# USB_USB2SS_OPER_31000020h register map
Vendor: Texas Instruments
Peripheral module from a debugger description file (folder am62D).
Registers are 32-bit, read-write, reset 0x0 unless marked. A register's access mark holds for its fields unless they carry their own. Offsets are as the file gives them; lines under a group give offsets from that group; [hi:lo] are bit positions; {n}, {i} and the like mark numbered series; 'fields as' and 'values as' point back to an identical list; <NAME> marks a mode.

## USB2SS_OPER
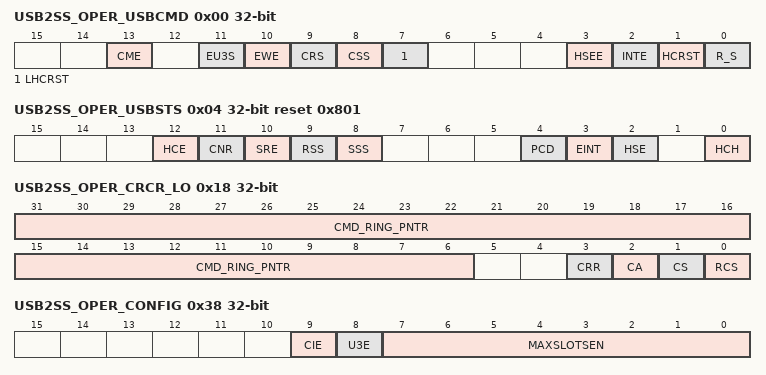
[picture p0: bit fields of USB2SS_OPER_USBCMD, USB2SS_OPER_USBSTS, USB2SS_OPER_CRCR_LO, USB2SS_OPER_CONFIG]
0x00 USB2SS_OPER_USBCMD — USB Command RegisterFor a description of this standard USB register field see the eXtensible Host Controller Interface for Universal Serial Bus (USB) Specification 3.0.
  [13] CME — CEM EnableFor a description of this standard USB register field, see the eXtensible Host Controller Interface for Universal Serial Bus [USB] Specification 3.0. Reset Source: rst_mod_g_rst_n
  [11] EU3S — EU3SFor a description of this standard USB register field, see the eXtensible Host Controller Interface for Universal Serial Bus [USB] Specification 3.0. Reset Source: rst_mod_g_rst_n
  [10] EWE — EWEFor a description of this standard USB register field, see the eXtensible Host Controller Interface for Universal Serial Bus [USB] Specification 3.0. Reset Source: rst_mod_g_rst_n
  [9] CRS — Controller Restore StateThis command is similar to the USBCMD.CRS bit in host mode and initiates the restore process. When software sets this bit to '1', the controller immediately sets DSTS.RSS to '1'. When the controller has finished the restore process, it sets DSTS.RSS to '0'.Note: When read, this field always returns '0'. Reset Source: rst_mod_g_rst_n
  [8] CSS — Controller Save StateThis command is similar to the USBCMD.CSS bit in host mode and initiates the save process. When software sets this bit to '1', the controller immediately sets DSTS.SSS to '1'. When the controller has finished the save process, it sets DSTS.SSS to '0'.Note: When read, this field always returns '0'. Reset Source: rst_mod_g_rst_n
  [7] LHCRST — Light Host Controller ResetFor a description of this standard USB register field, see the eXtensible Host Controller Interface for Universal Serial Bus [USB] Specification 3.0.The following bits reset the internal logic of the host controller. Under soft reset, some CSR accesses may fail [Timeout]. - HCRST - LHCRSTBit Bash register testing is not recommended. Reset Source: rst_mod_g_rst_n
  [3] HSEE — HSEEFor a description of this standard USB register field, see the eXtensible Host Controller Interface for Universal Serial Bus [USB] Specification 3.0. Reset Source: rst_mod_g_rst_n
  [2] INTE — INTEFor a description of this standard USB register field, see the eXtensible Host Controller Interface for Universal Serial Bus [USB] Specification 3.0. Reset Source: rst_mod_g_rst_n
  [1] HCRST — HCRSTThe following bits reset the internal logic of the host controller. Under soft reset, some CSR accesses may fail [Timeout]. - HCRST - LHCRSTBit Bash register testing is not recommended. Reset Source: rst_mod_g_rst_n
  [0] R_S — R_SFor a description of this standard USB register field, see the eXtensible Host Controller Interface for Universal Serial Bus [USB] Specification 3.0.Due to side-effects this reguster field is not recommended for Bit-Bash testing. Reset Source: rst_mod_g_rst_n
0x04 USB2SS_OPER_USBSTS access not given reset 0x801 — USB Status Register Bit DefinitionsFor a description of this standard USB register field, see the eXtensible Host Controller Interface for Universal Serial Bus (USB) Specification 3.0.
  [12] HCE ro — Host Controller Error [HCE] - RO Default = 0. '0' = No internal xHC error conditions exist and '1' = Internal xHC error condition. This flag must be set to indicate that an internal error condition has been detected which requires software to reset and reinitialize the xHC. Refer to section 4.24.1 of the Databook for more information. Reset Source: rst_mod_g_rst_n
  [11] CNR ro — Controller Not Ready [CNR] - RO Default = '1'. '0' = Ready and '1' = Not Ready. Software must not write to thes Doorbell or Operational register of the xHC, other than the USBSTS register, until CNR = '0'. This flag is set by the xHC after a Chip Hardware Reset and cleared when the xHC is ready to begin accepting register writes. This flag remains cleared ['0'] until the next Chip Hardware Reset. Reset Source: rst_mod_g_rst_n
  [10] SRE — Save/Restore ErrorThis bit is currently not supported. Reset Source: rst_mod_g_rst_n (access R/W1TC)
  [9] RSS ro — Restore State Status This bit is similar to the USBSTS.RSS in host mode.When the controller has finished the restore process, it completes the command by setting DSTS.RSS to '0'. Reset Source: rst_mod_g_rst_n
  [8] SSS ro — Save State StatusThis bit is similar to the USBSTS.SSS in host mode.When the controller has finished the save process, it completes the command by setting DSTS.SSS to '0'. Reset Source: rst_mod_g_rst_n
  [4] PCD — Reset Value for PCD Reset Source: rst_mod_g_rst_n (access R/W1TC)
  [3] EINT — Reset Value for EINT Reset Source: rst_mod_g_rst_n (access R/W1TC)
  [2] HSE — HSEFor a description of this standard USB register field, see the eXtensible Host Controller Interface for Universal Serial Bus [USB] Specification 3.0.. Reset Source: rst_mod_g_rst_n (access R/W1TC)
  [0] HCH ro — HCHFor a description of this standard USB register field, see the eXtensible Host Controller Interface for Universal Serial Bus [USB] Specification 3.0. Reset Source: rst_mod_g_rst_n
0x08 USB2SS_OPER_PAGESIZE ro reset 0x1 — Page Size Register Bit DefinitionsUse this register to enable or disable the reporting of specific USB Device Notification Transaction Packets being received.A Notification Enable (Nx, where x = 0 to 15) flag is defined for each of the 16 possible device notification types. If a flag is set for a specific notification type, a Device Notification Event is generated when the respective notification packet is received. After reset, all notifications are disabled. Refer to section 6.4.2.7 of the Databook for more information.This register is written as a Dword. Byte writes produce undefined results.
  [15:0] PAGE_SIZE — PAGE_SIZE Reset Source: rst_mod_g_rst_n
0x14 USB2SS_OPER_DNCTRL — Device Notification Register Bit DefinitionsFor a description of this standard USB register field see the eXtensible Host Controller Interface for Universal Serial Bus (USB) Specification 3.0.
  [15:0] N0_N15 — N0_N15For a description of this standard USB register field see the eXtensible Host Controller Interface for Universal Serial Bus [USB] Specification 3.0. Reset Source: rst_mod_g_rst_n
0x18 USB2SS_OPER_CRCR_LO access per field — CRCR_LOFor a description of this standard USB register field, see the eXtensible Host Controller Interface for Universal Serial Bus (USB) Specification 3.0.
  [31:6] CMD_RING_PNTR wo — CMD_RING_PNTRFor a description of this standard USB register field, see the eXtensible Host Controller Interface for Universal Serial Bus [USB] Specification 3.0. Reset Source: rst_mod_g_rst_n
  [3] CRR ro — CRRFor a description of this standard USB register field, see the eXtensible Host Controller Interface for Universal Serial Bus [USB] Specification 3.0. Reset Source: rst_mod_g_rst_n
  [2] CA wo — CAFor a description of this standard USB register field, see the eXtensible Host Controller Interface for Universal Serial Bus [USB] Specification 3.0. Reset Source: rst_mod_g_rst_n
  [1] CS wo — CSFor a description of this standard USB register field, see the eXtensible Host Controller Interface for Universal Serial Bus [USB] Specification 3.0. Reset Source: rst_mod_g_rst_n
  [0] RCS wo — RCSFor a description of this standard USB register field, see the eXtensible Host Controller Interface for Universal Serial Bus [USB] Specification 3.0. Reset Source: rst_mod_g_rst_n
0x1C USB2SS_OPER_CRCR_HI wo — CRCR_HI
  [31:0] CMD_RING_PNTR — COMMAND_RING_POINTER Reading this field always returns '0'.For a description of this standard USB register field, see the eXtensible Host Controller Interface for Universal Serial Bus [USB] Specification 3.0. Reset Source: rst_mod_g_rst_n
0x30 USB2SS_OPER_DCBAAP_LO — DCBAAP_LO
  [31:6] DEVICE_CONTEXT_BAAP — DEVICE_CONTEXT_BAAPFor a description of this standard USB register field, see the eXtensible Host Controller Interface for Universal Serial Bus [USB] Specification 3.0. Reset Source: rst_mod_g_rst_n
0x34 USB2SS_OPER_DCBAAP_HI — DCBAAP_HIFor a description of this standard USB register field, see the eXtensible Host Controller Interface for Universal Serial Bus (USB) Specification 3.0.
  [31:0] DEVICE_CONTEXT_BAAP — DEVICE_CONTEXT_BAAP Reset Source: rst_mod_g_rst_n
0x38 USB2SS_OPER_CONFIG — Configure Register Bit Definitions This register is in the Aux Power well. It is only reset by platform hardware during a cold reset or in response to a Host Controller Reset (HCRST). The initial conditions of a port are described in section 4.19 of the Databook.
  [9] CIE — Configuration Information EnableFor a description of this standard USB register field, see the eXtensible Host Controller Interface for Universal Serial Bus [USB] Specification 3.0. Reset Source: rst_mod_g_rst_n
  [8] U3E — U3 Entry EnableFor a description of this standard USB register field, see the eXtensible Host Controller Interface for Universal Serial Bus [USB] Specification 3.0. Reset Source: rst_mod_g_rst_n
  [7:0] MAXSLOTSEN — MAXSLOTSENFor a description of this standard USB register field, see the eXtensible Host Controller Interface for Universal Serial Bus [USB] Specification 3.0. Reset Source: rst_mod_g_rst_n
